# PIC32MX440F256H register map
Registers are 32-bit, access not given, reset 0x0 unless marked. A register's access mark holds for its fields unless they carry their own. Offsets are from the block's base; [hi:lo] are bit positions; {n}, {i} and the like mark numbered series; 'fields as' and 'values as' point back to an identical list.

## SPI2 — SPI2 peripheral
Base 0xBF805A00
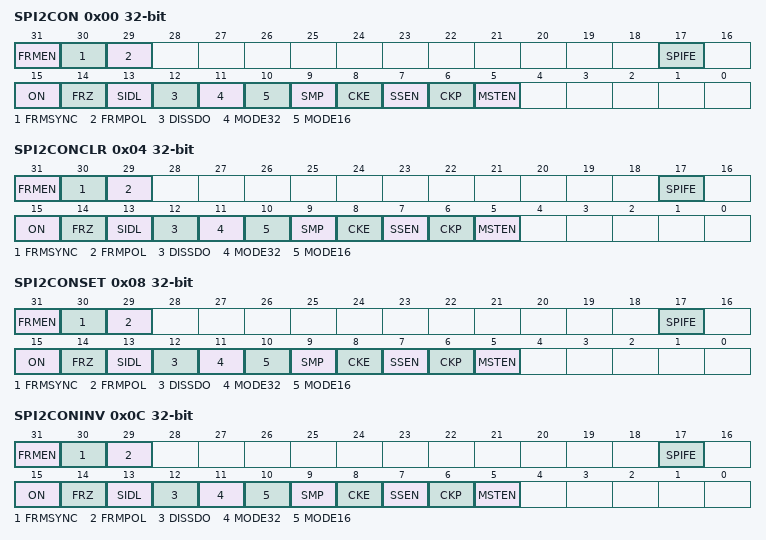
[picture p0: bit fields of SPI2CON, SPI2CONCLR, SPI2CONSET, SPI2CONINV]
0x00 SPI2CON
  [31] FRMEN, [30] FRMSYNC, [29] FRMPOL, [17] SPIFE, [15] ON, [14] FRZ, [13] SIDL, [12] DISSDO, [11] MODE32, [10] MODE16, [9] SMP, [8] CKE, [7] SSEN, [6] CKP, [5] MSTEN
0x04 SPI2CONCLR
  fields as SPI2CON
0x08 SPI2CONSET
  fields as SPI2CON
0x0C SPI2CONINV
  fields as SPI2CON
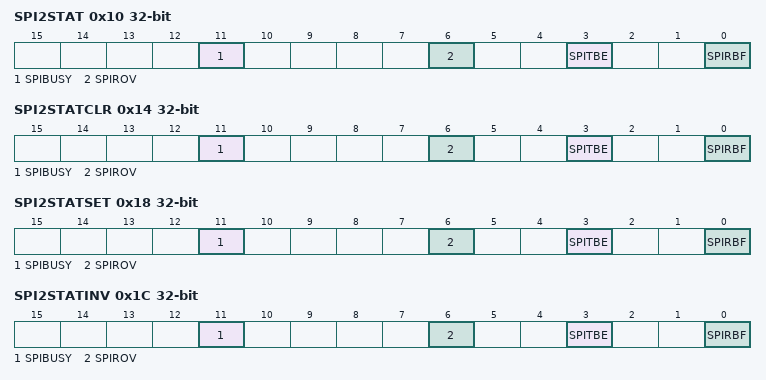
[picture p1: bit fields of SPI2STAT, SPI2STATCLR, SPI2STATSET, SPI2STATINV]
0x10 SPI2STAT
  [11] SPIBUSY, [6] SPIROV, [3] SPITBE, [0] SPIRBF
0x14 SPI2STATCLR
  [11] SPIBUSY, [6] SPIROV, [3] SPITBE, [0] SPIRBF
0x18 SPI2STATSET
  [11] SPIBUSY, [6] SPIROV, [3] SPITBE, [0] SPIRBF
0x1C SPI2STATINV
  [11] SPIBUSY, [6] SPIROV, [3] SPITBE, [0] SPIRBF
0x20 SPI2BUF
0x30 SPI2BRG
  [8:0] SPI2BRG
0x34 SPI2BRGCLR
  [8:0] SPI2BRG
0x38 SPI2BRGSET
  [8:0] SPI2BRG
0x3C SPI2BRGINV
  [8:0] SPI2BRG

## UART1 — UART1 peripheral
Base 0xBF806000
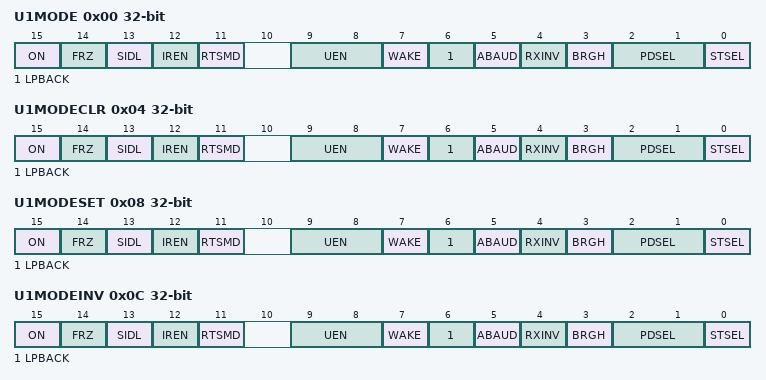
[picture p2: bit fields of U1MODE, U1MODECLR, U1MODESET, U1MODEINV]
0x00 U1MODE
  [15] ON, [14] FRZ, [13] SIDL, [12] IREN, [11] RTSMD, [9:8] UEN, [7] WAKE, [6] LPBACK, [5] ABAUD, [4] RXINV, [3] BRGH, [2:1] PDSEL, [0] STSEL
0x04 U1MODECLR
  fields as U1MODE
0x08 U1MODESET
  fields as U1MODE
0x0C U1MODEINV
  fields as U1MODE
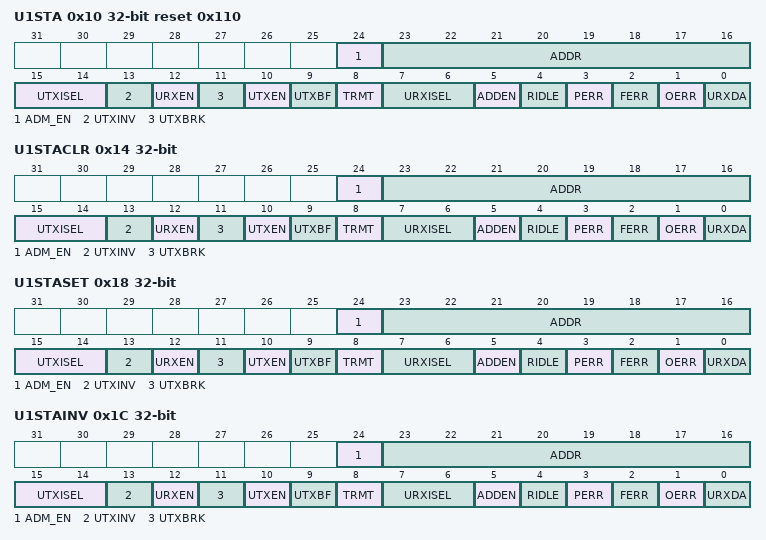
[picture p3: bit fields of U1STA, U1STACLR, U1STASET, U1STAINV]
0x10 U1STA reset 0x110
  [24] ADM_EN, [23:16] ADDR, [15:14] UTXISEL, [13] UTXINV, [12] URXEN, [11] UTXBRK, [10] UTXEN, [9] UTXBF, [8] TRMT, [7:6] URXISEL, [5] ADDEN, [4] RIDLE, [3] PERR, [2] FERR, [1] OERR, [0] URXDA
0x14 U1STACLR
  fields as U1STA
0x18 U1STASET
  fields as U1STA
0x1C U1STAINV
  fields as U1STA
0x20 U1TXREG
  [8:0] U1TXREG
0x30 U1RXREG
  [8:0] U1RXREG
0x40 U1BRG
  [15:0] BRG
0x44 U1BRGCLR
  [15:0] BRG
0x48 U1BRGSET
  [15:0] BRG
0x4C U1BRGINV
  [15:0] BRG

## UART2 — UART2 peripheral
Base 0xBF806200
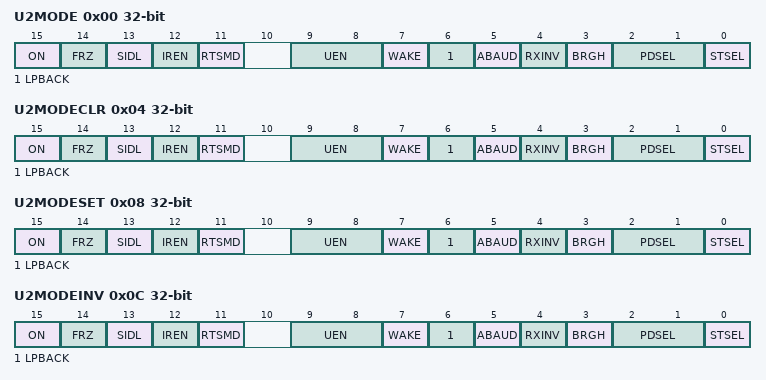
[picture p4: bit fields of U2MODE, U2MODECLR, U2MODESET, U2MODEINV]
0x00 U2MODE
  [15] ON, [14] FRZ, [13] SIDL, [12] IREN, [11] RTSMD, [9:8] UEN, [7] WAKE, [6] LPBACK, [5] ABAUD, [4] RXINV, [3] BRGH, [2:1] PDSEL, [0] STSEL
0x04 U2MODECLR
  fields as U2MODE
0x08 U2MODESET
  fields as U2MODE
0x0C U2MODEINV
  fields as U2MODE
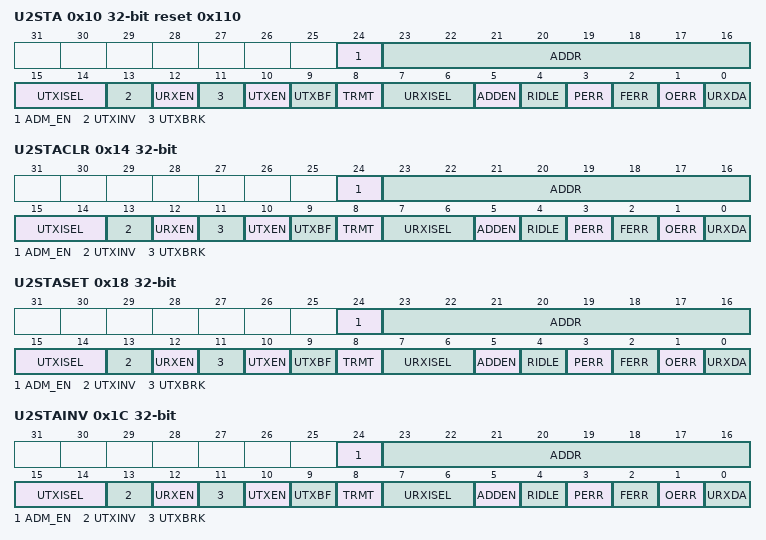
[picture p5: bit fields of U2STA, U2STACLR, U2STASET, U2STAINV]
0x10 U2STA reset 0x110
  [24] ADM_EN, [23:16] ADDR, [15:14] UTXISEL, [13] UTXINV, [12] URXEN, [11] UTXBRK, [10] UTXEN, [9] UTXBF, [8] TRMT, [7:6] URXISEL, [5] ADDEN, [4] RIDLE, [3] PERR, [2] FERR, [1] OERR, [0] URXDA
0x14 U2STACLR
  fields as U2STA
0x18 U2STASET
  fields as U2STA
0x1C U2STAINV
  fields as U2STA
0x20 U2TXREG
  [8:0] U2TXREG
0x30 U2RXREG
  [8:0] U2RXREG
0x40 U2BRG
  [15:0] BRG
0x44 U2BRGCLR
  [15:0] BRG
0x48 U2BRGSET
  [15:0] BRG
0x4C U2BRGINV
  [15:0] BRG

## PMP — PMP peripheral
Base 0xBF807000
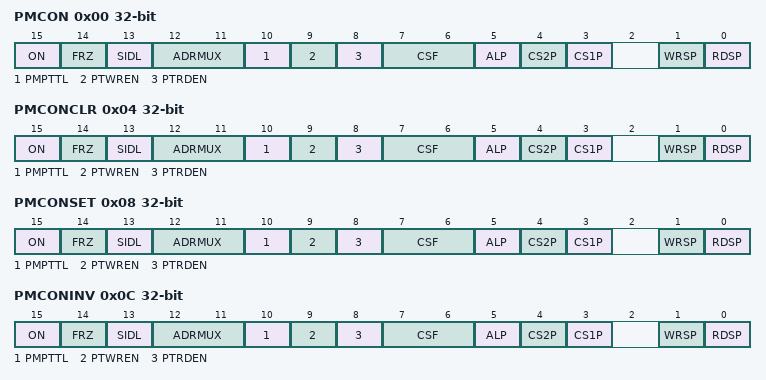
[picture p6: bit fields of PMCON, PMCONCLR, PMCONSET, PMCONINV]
0x00 PMCON
  [15] ON, [14] FRZ, [13] SIDL, [12:11] ADRMUX, [10] PMPTTL, [9] PTWREN, [8] PTRDEN, [7:6] CSF, [5] ALP, [4] CS2P, [3] CS1P, [1] WRSP, [0] RDSP
0x04 PMCONCLR
  fields as PMCON
0x08 PMCONSET
  fields as PMCON
0x0C PMCONINV
  fields as PMCON
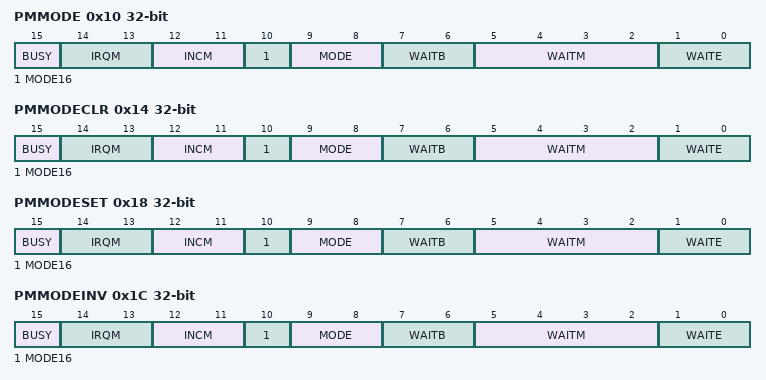
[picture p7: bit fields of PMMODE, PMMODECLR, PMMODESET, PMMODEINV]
0x10 PMMODE
  [15] BUSY, [14:13] IRQM, [12:11] INCM, [10] MODE16, [9:8] MODE, [7:6] WAITB, [5:2] WAITM, [1:0] WAITE
0x14 PMMODECLR
  fields as PMMODE
0x18 PMMODESET
  fields as PMMODE
0x1C PMMODEINV
  fields as PMMODE
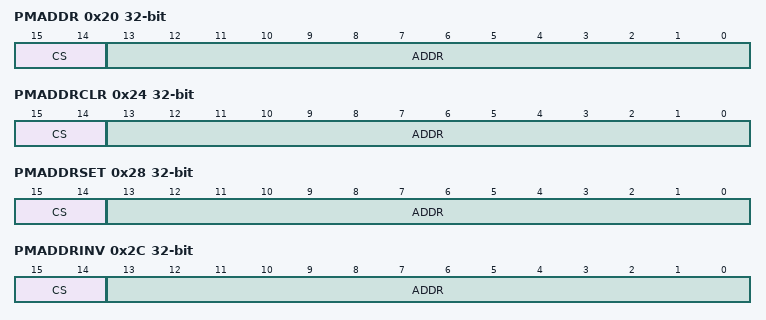
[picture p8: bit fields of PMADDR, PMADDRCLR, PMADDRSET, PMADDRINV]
0x20 PMADDR
  [15:14] CS, [13:0] ADDR
0x24 PMADDRCLR
  [15:14] CS, [13:0] ADDR
0x28 PMADDRSET
  [15:14] CS, [13:0] ADDR
0x2C PMADDRINV
  [15:14] CS, [13:0] ADDR
0x30 PMDOUT
  [31:0] DATAOUT
0x34 PMDOUTCLR
  [31:0] DATAOUT
0x38 PMDOUTSET
  [31:0] DATAOUT
0x3C PMDOUTINV
  [31:0] DATAOUT
0x40 PMDIN
  [31:0] DATAIN
0x44 PMDINCLR
  [31:0] DATAIN
0x48 PMDINSET
  [31:0] DATAIN
0x4C PMDININV
  [31:0] DATAIN
0x50 PMAEN
  [15:0] PTEN
0x54 PMAENCLR
  [15:0] PTEN
0x58 PMAENSET
  [15:0] PTEN
0x5C PMAENINV
  [15:0] PTEN
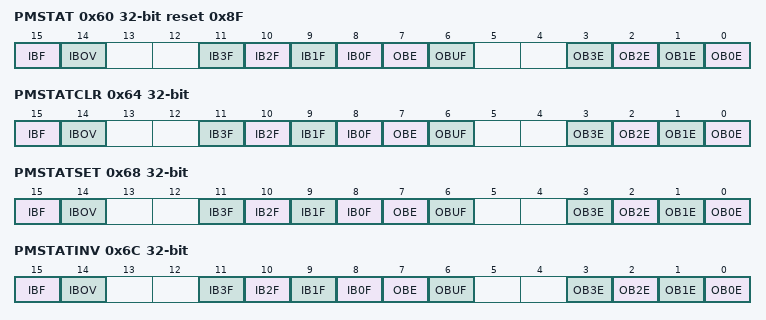
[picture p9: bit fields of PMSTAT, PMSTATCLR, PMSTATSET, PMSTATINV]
0x60 PMSTAT reset 0x8F
  [15] IBF, [14] IBOV, [n+8] IB{n}F (n=0..3), [7] OBE, [6] OBUF, [n] OB{n}E (n=0..3)
0x64 PMSTATCLR
  fields as PMSTAT
0x68 PMSTATSET
  fields as PMSTAT
0x6C PMSTATINV
  fields as PMSTAT

## ADC10 — ADC10 peripheral
Base 0xBF809000
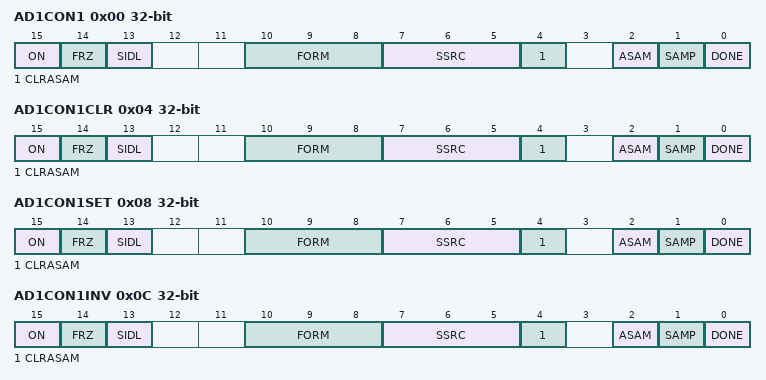
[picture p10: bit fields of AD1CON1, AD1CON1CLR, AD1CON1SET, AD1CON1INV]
0x00 AD1CON1
  [15] ON, [14] FRZ, [13] SIDL, [10:8] FORM, [7:5] SSRC, [4] CLRASAM, [2] ASAM, [1] SAMP, [0] DONE
0x04 AD1CON1CLR
  fields as AD1CON1
0x08 AD1CON1SET
  fields as AD1CON1
0x0C AD1CON1INV
  fields as AD1CON1
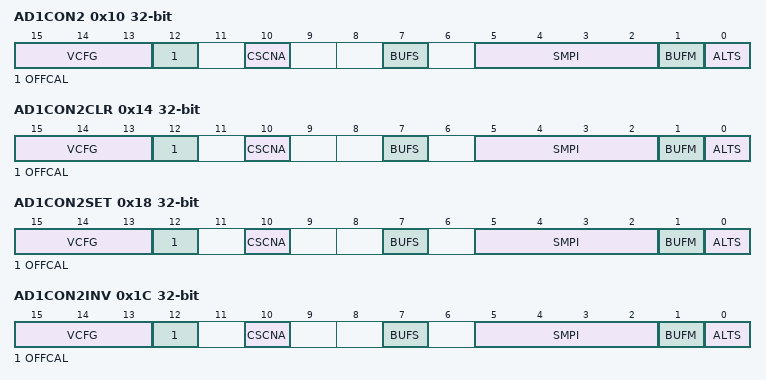
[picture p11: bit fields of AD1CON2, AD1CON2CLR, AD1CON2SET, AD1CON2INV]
0x10 AD1CON2
  [15:13] VCFG, [12] OFFCAL, [10] CSCNA, [7] BUFS, [5:2] SMPI, [1] BUFM, [0] ALTS
0x14 AD1CON2CLR
  fields as AD1CON2
0x18 AD1CON2SET
  fields as AD1CON2
0x1C AD1CON2INV
  fields as AD1CON2
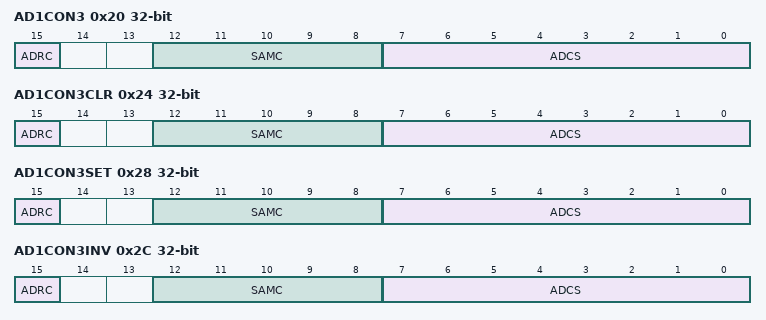
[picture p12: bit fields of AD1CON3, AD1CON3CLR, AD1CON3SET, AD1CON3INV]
0x20 AD1CON3
  [15] ADRC, [12:8] SAMC, [7:0] ADCS
0x24 AD1CON3CLR
  [15] ADRC, [12:8] SAMC, [7:0] ADCS
0x28 AD1CON3SET
  [15] ADRC, [12:8] SAMC, [7:0] ADCS
0x2C AD1CON3INV
  [15] ADRC, [12:8] SAMC, [7:0] ADCS
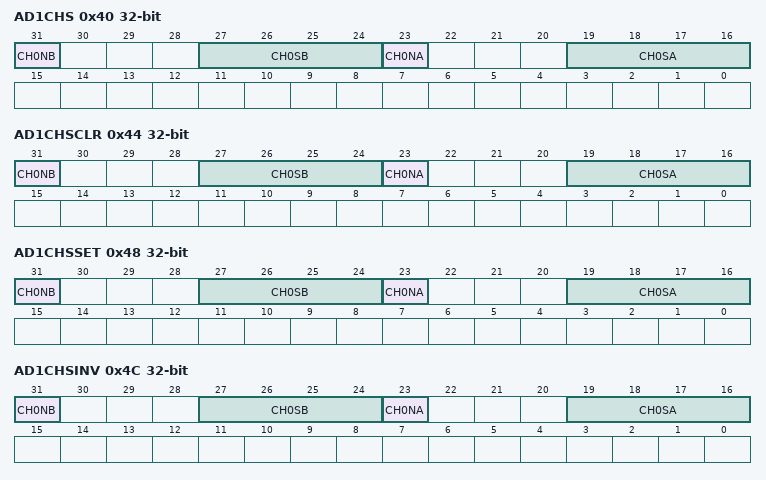
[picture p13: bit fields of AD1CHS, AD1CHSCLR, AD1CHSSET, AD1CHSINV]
0x40 AD1CHS
  [31] CH0NB, [27:24] CH0SB, [23] CH0NA, [19:16] CH0SA
0x44 AD1CHSCLR
  [31] CH0NB, [27:24] CH0SB, [23] CH0NA, [19:16] CH0SA
0x48 AD1CHSSET
  [31] CH0NB, [27:24] CH0SB, [23] CH0NA, [19:16] CH0SA
0x4C AD1CHSINV
  [31] CH0NB, [27:24] CH0SB, [23] CH0NA, [19:16] CH0SA
0x50 AD1CSSL
  [15:0] CSSL
0x54 AD1CSSLCLR
  [15:0] CSSL
0x58 AD1CSSLSET
  [15:0] CSSL
0x5C AD1CSSLINV
  [15:0] CSSL
0x60 AD1PCFG
  [15:0] PCFG
0x64 AD1PCFGCLR
  [15:0] PCFG
0x68 AD1PCFGSET
  [15:0] PCFG
0x6C AD1PCFGINV
  [15:0] PCFG
{0x70+0x10*i} ADC1BUF{i} (i=0..9)
0x110 ADC1BUFA
0x120 ADC1BUFB
0x130 ADC1BUFC
0x140 ADC1BUFD
0x150 ADC1BUFE
0x160 ADC1BUFF
